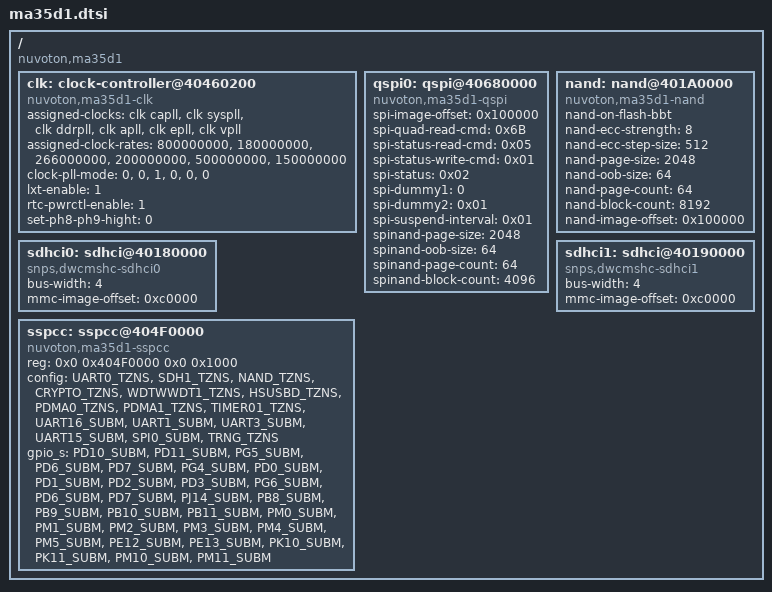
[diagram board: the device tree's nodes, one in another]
/*
 * Device Tree Source for MA35D1
 *
 * Copyright (C) 2020 Nuvoton Technology Corp.
 *
 * The code contained herein is licensed under the GNU General Public
 * License. You may obtain a copy of the GNU General Public License
 * Version 2 or later at the following locations:
 *
 * http://www.opensource.org/licenses/gpl-license.html
 * http://www.gnu.org/copyleft/gpl.html
 */
/dts-v1/;

#include <dt-bindings/clock/ma35d1-clk.h>
#include "../plat/nuvoton/ma35d1/include/sspcc.h"

/{
	compatible = "nuvoton,ma35d1";
	#address-cells = <2>;
	#size-cells = <2>;

	clk: clock-controller@40460200 {
		compatible = "nuvoton,ma35d1-clk", "syscon", "simple-mfd";
		#clock-cells = <1>;
		assigned-clocks = <&clk capll>, <&clk syspll>,
				<&clk ddrpll>, <&clk apll>,
				<&clk epll>, <&clk vpll>;
		assigned-clock-rates =<800000000>, <180000000>,
				<266000000>, <200000000>,
				<500000000>, <150000000>;
		clock-pll-mode = <0>, <0>, <1>, <0>, <0>, <0>;
		lxt-enable = <1>;
		/* rtc power control */
		rtc-pwrctl-enable = <1>;
		/* Set PH8/PH9 output hight */
		set-ph8-ph9-hight = <0>;
	};

	qspi0: qspi@40680000 {
		compatible = "nuvoton,ma35d1-qspi";

		/* spi information */
		spi-image-offset = <0x100000>;
		spi-quad-read-cmd = <0x6B>;
		spi-status-read-cmd = <0x05>;
		spi-status-write-cmd = <0x01>;
		spi-status = <0x02>;
		spi-dummy1 = <0>;
		spi-dummy2 = <0x01>;
		spi-suspend-interval = <0x01>;

		/* spi-nand information */
		spinand-page-size = <2048>;
		spinand-oob-size = <64>;
		spinand-page-count = <64>;
		spinand-block-count = <4096>;
	};

	nand: nand@401A0000 {
		compatible = "nuvoton,ma35d1-nand";

		nand-on-flash-bbt;
		/* nand information */
		nand-ecc-strength = <8>;
		nand-ecc-step-size = <512>;
		nand-page-size = <2048>;
		nand-oob-size = <64>;
		nand-page-count = <64>;
		nand-block-count = <8192>;
		nand-image-offset = <0x100000>;
	};

	sdhci0: sdhci@40180000 {
		compatible = "snps,dwcmshc-sdhci0";
		bus-width = <4>;
		/* sdhc information */
		mmc-image-offset = <0xc0000>;
	};

	sdhci1: sdhci@40190000 {
		compatible = "snps,dwcmshc-sdhci1";
		bus-width = <4>;
		/* sdhc information */
		mmc-image-offset = <0xc0000>;
	};

	sspcc: sspcc@404F0000 {
		compatible = "nuvoton,ma35d1-sspcc";
		reg = <0x0 0x404F0000 0x0 0x1000>;
		config = <UART0_TZNS>,
			/*<SDH0_TZNS>,*/
			<SDH1_TZNS>,
			<NAND_TZNS>,
			/*<QSPI0_TZNS>,*/
			<CRYPTO_TZNS>,
			<WDTWWDT1_TZNS>,
			<HSUSBD_TZNS>,
			<PDMA0_TZNS>,
			<PDMA1_TZNS>,
			<TIMER01_TZNS>,
			<UART16_SUBM>,
			<UART1_SUBM>,			
			<UART3_SUBM>,			
			<UART15_SUBM>,	
			<SPI0_SUBM>,
			/*<I2C2_SUBM>,*/
			<TRNG_TZNS>;
		gpio_s = <PD10_SUBM>,	/* UART16 TxRx:PD10~11 Pwr:PG5 */
			<PD11_SUBM>,
			<PG5_SUBM>,
			<PD6_SUBM>,			/* UART1 TxRx:PD6~7 Pwr:PG4 */
			<PD7_SUBM>,			
			<PG4_SUBM>,
			<PD0_SUBM>,			/* UART3 TxRxRtsCts:PD0~3 Pwr:PG6 */
			<PD1_SUBM>,			
			<PD2_SUBM>,
			<PD3_SUBM>,			
			<PG6_SUBM>,	
			<PD6_SUBM>,			/* UART15 TxRx:PD8~9 DE:PJ14*/
			<PD7_SUBM>,			
			<PJ14_SUBM>,			
			<PB8_SUBM>,			/* SPI0 PB8~11 Rst:PM0 HRDY:PM1 */
			<PB9_SUBM>,			
			<PB10_SUBM>,
			<PB11_SUBM>,			
			<PM0_SUBM>,	
			<PM1_SUBM>,	
			/*<PD4_SUBM>,			I2C2 PD4~5 Rst:PC6 INT:PL14 
			<PD5_SUBM>,			
			<PC6_SUBM>,
			<PL14_SUBM>,*/		
			<PM2_SUBM>,			/* Key PM2~5 */
			<PM3_SUBM>,
			<PM4_SUBM>,
			<PM5_SUBM>,
			<PE12_SUBM>,		/* Buzzer PE12~13 */
			<PE13_SUBM>,
			<PK10_SUBM>,		/* LED Blue PK10 */
			<PK11_SUBM>,		/* LED Green PK11 */
			<PM10_SUBM>,		/* LED Orange PM10 */
			<PM11_SUBM>;		/* LED Red PM11 */
	};
};
